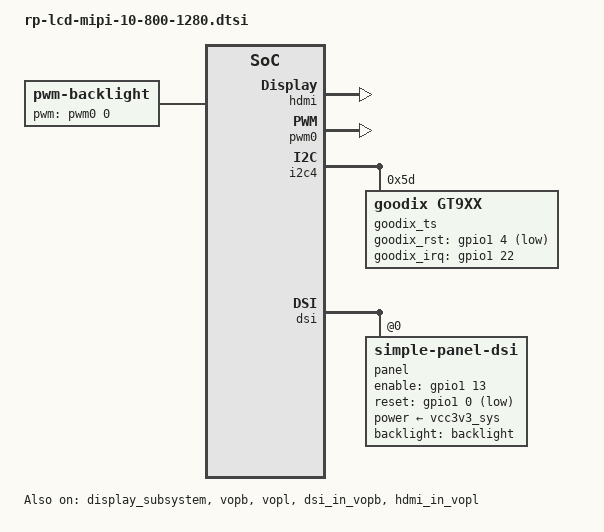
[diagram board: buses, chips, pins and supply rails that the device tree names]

/ {
	
	backlight: backlight {
		status = "okay";
		compatible = "pwm-backlight";
		pwms = <&pwm0 0 25000 0>;
		brightness-levels = <
			  0   1   2   3   4   5   6   7
			  8   9  10  11  12  13  14  15
			 16  17  18  19  20  21  22  23
			 24  25  26  27  28  29  30  31
			 32  33  34  35  36  37  38  39
			 40  41  42  43  44  45  46  47
			 48  49  50  51  52  53  54  55
			 56  57  58  59  60  61  62  63
			 64  65  66  67  68  69  70  71
			 72  73  74  75  76  77  78  79
			 80  81  82  83  84  85  86  87
			 88  89  90  91  92  93  94  95
			 96  97  98  99 100 101 102 103
			104 105 106 107 108 109 110 111
			112 113 114 115 116 117 118 119
			120 121 122 123 124 125 126 127
			128 129 130 131 132 133 134 135
			136 137 138 139 140 141 142 143
			144 145 146 147 148 149 150 151
			152 153 154 155 156 157 158 159
			160 161 162 163 164 165 166 167
			168 169 170 171 172 173 174 175
			176 177 178 179 180 181 182 183
			184 185 186 187 188 189 190 191
			192 193 194 195 196 197 198 199
			200 201 202 203 204 205 206 207
			208 209 210 211 212 213 214 215
			216 217 218 219 220 221 222 223
			224 225 226 227 228 229 230 231
			232 233 234 235 236 237 238 239
			240 241 242 243 244 245 246 247
			248 249 250 251 252 253 254 255>;
		default-brightness-level = <255>;
	};

	//bill  
        rpdzkj_config {
                compatible = "rp_config";
                user_version = "rpdzkj";
                system_rotate = "0";
                back_camera_rotate = "0";
                front_camera_rotate = "0";
                lcd_density = "160";
                language = "zh-CN";   //zh-CN //en-US
                time_zone = "Asia/Shanghai"; //Asia/Shanghai = +8   //Europe/London  = +0
                not_navigation_bar = "false";
                not_status_bar = "false";
                default_launcher = "true";
                has_root = "true";  //true//false
                usb_not_permission = "true";  
                usb_camera_only_front = "false";
                gps_use = "false";
                gps_serial_port = "/dev/ttyS4"; //UART4
                status = "okay";
        };

};


&hdmi {
	#address-cells = <1>;
	#size-cells = <0>;
	#sound-dai-cells = <0>;
	ddc-i2c-scl-high-time-ns = <9625>;
	ddc-i2c-scl-low-time-ns = <10000>;
	status = "okay";
};

&pwm0 {
	status = "okay";
};

&i2c4 {
        status = "okay";
	
	goodix_ts@5d {
		compatible = "goodix,gt9xx";
		reg = <0x5d>;
		
		goodix_rst_gpio = <&gpio1 4 GPIO_ACTIVE_LOW>;
		goodix_irq_gpio = <&gpio1 22 IRQ_TYPE_EDGE_RISING>;
/* old touchscreen sensor_id0 */
	        goodix,cfg-group0 = [
			00 20 03 00 05 0A 05 00 01 08 
			28 05 50 32 03 05 00 00 00 00 
			00 00 00 00 00 00 00 90 30 AA 
			17 15 31 0D 00 00 01 B9 04 25 
			00 00 00 00 00 00 00 00 00 00 
			00 0F 23 94 C5 02 07 00 00 04 
			9F 10 00 8B 13 00 7C 16 00 6B 
			1B 00 60 20 00 60 00 00 00 00 
			00 00 00 00 00 00 00 00 00 00 
			00 00 00 00 00 00 00 00 00 00 
			00 00 00 00 00 00 00 00 00 00 
			00 00 19 18 17 16 15 14 11 10 
			0F 0E 0D 0C 09 08 07 06 05 04 
			01 00 00 00 00 00 00 00 00 00 
			00 00 2A 29 28 27 26 25 24 23 
			22 21 20 1F 1E 1C 1B 19 00 02 
			04 06 07 08 0A 0C 0D 0E 0F 10 
			11 12 13 14 00 00 00 00 00 00 
			00 00 00 00 96 01
		];	
/* new touchscreen sensor_id2 */					
                goodix,cfg-group2 = [
					 00 20 03 00 05 0A 35 00 00
					 05 28 08 55 41 03 05 00 00
					 00 00 00 00 00 1A 1C 1E 14
					 8E 2E 99 14 16 D3 07 00 00
					 00 9B 02 2D 00 00 00 00 00
					 00 00 00 00 00 00 0F 23 94
					 D5 02 07 00 00 04 9D 10 00
					 86 13 00 75 16 00 61 1B 00
					 53 20 00 53 00 00 00 00 00
					 00 00 00 00 00 00 00 00 00
					 00 00 00 00 00 00 00 00 00
					 00 00 00 00 00 00 00 00 00
					 00 00 00 00 17 16 15 14 11
					 10 0F 0E 0D 0C 09 08 07 06
					 05 04 01 00 FF FF 00 00 00
					 00 00 00 00 00 00 00 00 02
					 04 06 07 08 0A 0C 0D 0F 10
					 11 12 13 28 27 26 25 24 23
					 22 21 20 1F 1E 1C 1B 19 FF
					 FF FF FF 00 00 00 00 00 00
					 00 00 00 00 4D 01
				 ];

	};
};

&display_subsystem {
	status = "okay";
	ports = <&vopb_out>, <&vopl_out>;
	logo-memory-region = <&drm_logo>;

	route {
		route_hdmi: route-hdmi {
			status = "okay";
			logo,uboot = "logo.bmp";
			logo,kernel = "logo_kernel.bmp";
                        logo,mode = "center";
			charge_logo,mode = "center";
			connect = <&vopl_out_hdmi>;
		};

		route_dsi: route-dsi {

			status = "okay";
			logo,uboot = "logo.bmp";
			logo,kernel = "logo_kernel.bmp";
			logo,mode = "center";
			charge_logo,mode = "center";
			connect = <&vopb_out_dsi>;
		};

		route_dsi1: route-dsi1 {
			status = "disabled";
			logo,uboot = "logo.bmp";
			logo,kernel = "logo_kernel.bmp";
			logo,mode = "fullscreen";
			charge_logo,mode = "center";
			connect = <&vopl_out_dsi1>;
		};

		route_edp: route-edp {
			status = "disabled";
			logo,uboot = "logo.bmp";
			logo,kernel = "logo_kernel.bmp";
			logo,mode = "fullscreen";
			charge_logo,mode = "center";
			connect = <&vopb_out_edp>;
		};
	};
};

&dsi {
        status = "okay";
	
	panel {
		compatible ="simple-panel-dsi"; 
		status = "okay"; 
		reg = <0>; 
		power-supply = <&vcc3v3_sys>; 
		backlight = <&backlight>; 
		cmd_later_reset = <0>; 
		prepare-delay-ms = <100>;
		reset-delay-ms = <10>;
		init-delay-ms = <100>;
		enable-delay-ms = <120>;
		disable-delay-ms = <50>;
		unprepare-delay-ms = <20>;
		enable-gpios = <&gpio1 13 GPIO_ACTIVE_HIGH>; 
		reset-gpios  = <&gpio1 0 GPIO_ACTIVE_LOW>; 
		dsi,flags = <(MIPI_DSI_MODE_VIDEO | MIPI_DSI_MODE_VIDEO_BURST | MIPI_DSI_MODE_LPM|MIPI_DSI_MODE_EOT_PACKET)>; 
		dsi,format = <MIPI_DSI_FMT_RGB888>; 
//		bus-format = <MEDIA_BUS_FMT_RGB666_1X24>;
                dsi,lanes = <4>;
					//for king/rp/rd board cannot enable boot logo
                                        pinctrl-names = "default";
                                        pinctrl-0 = <&pwr_en>;

               	panel-init-sequence = [
			15 00 02 E0 00
			15 00 02 E1 93
			15 00 02 E2 65
			15 00 02 E3 F8
			15 00 02 E0 04
			15 00 02 2D 03
			15 00 02 E0 00
			15 00 02 80 03
			15 00 02 70 02
			15 00 02 71 23
			15 00 02 72 06
			15 00 02 E0 01
			15 00 02 00 00
			15 00 02 01 66
			15 00 02 03 00
			15 00 02 04 6D
			15 00 02 17 00
			15 00 02 18 BF
			15 00 02 19 00
			15 00 02 1A 00
			15 00 02 1B BF
			15 00 02 1C 00
			15 00 02 1F 3E
			15 00 02 20 28
			15 00 02 21 28
			15 00 02 22 0E
			15 00 02 37 09
			15 00 02 38 04
			15 00 02 39 08
			15 00 02 3A 12
			15 00 02 3C 78
			15 00 02 3D FF
			15 00 02 3E FF
			15 00 02 3F 7F
			15 00 02 40 06
			15 00 02 41 A0
			15 00 02 55 0F
			15 00 02 56 01
			15 00 02 57 69
			15 00 02 58 0A
			15 00 02 59 0A
			15 00 02 5A 29
			15 00 02 5B 15
			15 00 02 5D 7C
			15 00 02 5E 65
			15 00 02 5F 55
			15 00 02 60 49
			15 00 02 61 44
			15 00 02 62 35
			15 00 02 63 3A
			15 00 02 64 23
			15 00 02 65 3D
			15 00 02 66 3C
			15 00 02 67 3D
			15 00 02 68 5D
			15 00 02 69 4D
			15 00 02 6A 56
			15 00 02 6B 48
			15 00 02 6C 45
			15 00 02 6D 38
			15 00 02 6E 25
			15 00 02 6F 00
			15 00 02 70 7C
			15 00 02 71 65
			15 00 02 72 55
			15 00 02 73 49
			15 00 02 74 44
			15 00 02 75 35
			15 00 02 76 3A
			15 00 02 77 23
			15 00 02 78 3D
			15 00 02 79 3C
			15 00 02 7A 3D
			15 00 02 7B 5D
			15 00 02 7C 4D
			15 00 02 7D 56
			15 00 02 7E 48
			15 00 02 7F 45
			15 00 02 80 38
			15 00 02 81 25
			15 00 02 82 00
			15 00 02 E0 02
			15 00 02 00 1E
			15 00 02 01 1E
			15 00 02 02 41
			15 00 02 03 41
			15 00 02 04 43
			15 00 02 05 43
			15 00 02 06 1F
			15 00 02 07 1F
			15 00 02 08 1F
			15 00 02 09 1F
			15 00 02 0A 1E
			15 00 02 0B 1E
			15 00 02 0C 1F
			15 00 02 0D 47
			15 00 02 0E 47
			15 00 02 0F 45
			15 00 02 10 45
			15 00 02 11 4B
			15 00 02 12 4B
			15 00 02 13 49
			15 00 02 14 49
			15 00 02 15 1F
			15 00 02 16 1E
			15 00 02 17 1E
			15 00 02 18 40
			15 00 02 19 40
			15 00 02 1A 42
			15 00 02 1B 42
			15 00 02 1C 1F
			15 00 02 1D 1F
			15 00 02 1E 1F
			15 00 02 1F 1f
			15 00 02 20 1E
			15 00 02 21 1E
			15 00 02 22 1f
			15 00 02 23 46
			15 00 02 24 46
			15 00 02 25 44
			15 00 02 26 44
			15 00 02 27 4A
			15 00 02 28 4A
			15 00 02 29 48
			15 00 02 2A 48
			15 00 02 2B 1f
			15 00 02 2C 1F
			15 00 02 2D 1F
			15 00 02 2E 42
			15 00 02 2F 42
			15 00 02 30 40
			15 00 02 31 40
			15 00 02 32 1E
			15 00 02 33 1E
			15 00 02 34 1F
			15 00 02 35 1F
			15 00 02 36 1E
			15 00 02 37 1E
			15 00 02 38 1F
			15 00 02 39 48
			15 00 02 3A 48
			15 00 02 3B 4A
			15 00 02 3C 4A
			15 00 02 3D 44
			15 00 02 3E 44
			15 00 02 3F 46
			15 00 02 40 46
			15 00 02 41 1F
			15 00 02 42 1F
			15 00 02 43 1F
			15 00 02 44 43
			15 00 02 45 43
			15 00 02 46 41
			15 00 02 47 41
			15 00 02 48 1E
			15 00 02 49 1E
			15 00 02 4A 1E
			15 00 02 4B 1F
			15 00 02 4C 1E
			15 00 02 4D 1E
			15 00 02 4E 1F
			15 00 02 4F 49
			15 00 02 50 49
			15 00 02 51 4B
			15 00 02 52 4B
			15 00 02 53 45
			15 00 02 54 45
			15 00 02 55 47
			15 00 02 56 47
			15 00 02 57 1F
			15 00 02 58 10
			15 00 02 59 00
			15 00 02 5A 00
			15 00 02 5B 30
			15 00 02 5C 02
			15 00 02 5D 40
			15 00 02 5E 01
			15 00 02 5F 02
			15 00 02 60 30
			15 00 02 61 01
			15 00 02 62 02
			15 00 02 63 6A
			15 00 02 64 6A
			15 00 02 65 05
			15 00 02 66 12
			15 00 02 67 74
			15 00 02 68 04
			15 00 02 69 6A
			15 00 02 6A 6A
			15 00 02 6B 08
			15 00 02 6C 00
			15 00 02 6D 06
			15 00 02 6E 00
			15 00 02 6F 88
			15 00 02 70 00
			15 00 02 71 00
			15 00 02 72 06
			15 00 02 73 7B
			15 00 02 74 00
			15 00 02 75 07
			15 00 02 76 00
			15 00 02 77 5D
			15 00 02 78 17
			15 00 02 79 1F
			15 00 02 7A 00
			15 00 02 7B 00
			15 00 02 7C 00
			15 00 02 7D 03
			15 00 02 7E 7B
			15 00 02 E0 04
			15 00 02 2B 2B
			15 00 02 2E 44
			15 00 02 E0 01
			15 00 02 0E 01
			15 00 02 E0 03
			15 00 02 98 2F
			15 00 02 E0 00
			15 00 02 E6 02
			15 00 02 E7 02

                        05 78 01 11
                        05 05 01 29
                        15 0a 02 35 00
                ];

                panel-exit-sequence = [
                        05 00 01 28
                        05 78 01 10
                ];

                display-timings {
                        native-mode = <&timing0>;
                        timing0: timing0 {
                                clock-frequency = <68000000>;
                                hactive = <800>;
                                vactive = <1280>;
                                hback-porch = <18>;
                                hfront-porch = <18>;
                                vback-porch = <8>;
                                vfront-porch = <24>;
                                hsync-len = <18>;
                                vsync-len = <4>;
                                hsync-active = <0>;
                                vsync-active = <0>;
                                de-active = <0>;
                                pixelclk-active = <0>;
                        };
                        timing1: timing1 {
                                clock-frequency = <148000000>;
                                hactive = <1920>;
                                vactive = <1080>;
                                hback-porch = <100>;
                                hfront-porch = <160>;
                                vback-porch = <25>;
                                vfront-porch = <10>;
                                hsync-len = <20>;
                                vsync-len = <10>;
                                hsync-active = <0>;
                                vsync-active = <0>;
                                de-active = <0>;
                                pixelclk-active = <1>;
                        };
                };
        };
};

&vopb {
        assigned-clocks = <&cru DCLK_VOP0_DIV>;
        assigned-clock-parents = <&cru PLL_CPLL>;
        //assigned-clock-parents = <&cru PLL_VPLL>;
        status = "okay";
};

&vopb_mmu {
        status = "okay";
};

&vopl {
        assigned-clocks = <&cru DCLK_VOP1_DIV>;
        assigned-clock-parents = <&cru PLL_VPLL>;
        //assigned-clock-parents = <&cru PLL_CPLL>;
        status = "okay";
};

&vopl_mmu {
        status = "okay";
};

&dsi_in_vopl { 
        status = "disabled"; 
}; 

&dsi_in_vopb {
	status = "okay";
}; 

&hdmi_in_vopb { 
        status = "disabled"; 
}; 
 
&hdmi_in_vopl {
	status = "okay";
};

&edp_in_vopb { 
        status = "disabled"; 
}; 
&edp_in_vopl { 
        status = "disabled"; 
}; 

&dsi1_in_vopb { 
        status = "disabled"; 
}; 
&dsi1_in_vopl { 
        status = "disabled"; 
}; 

&pinctrl{
        pwr_5v {
                        pwr_en: pwr-en {
                                rockchip,pins = //<6 5 RK_FUNC_GPIO &pcfg_pull_up>,
                                                <4 30 RK_FUNC_GPIO &pcfg_pull_up>;
                        };
        };
};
